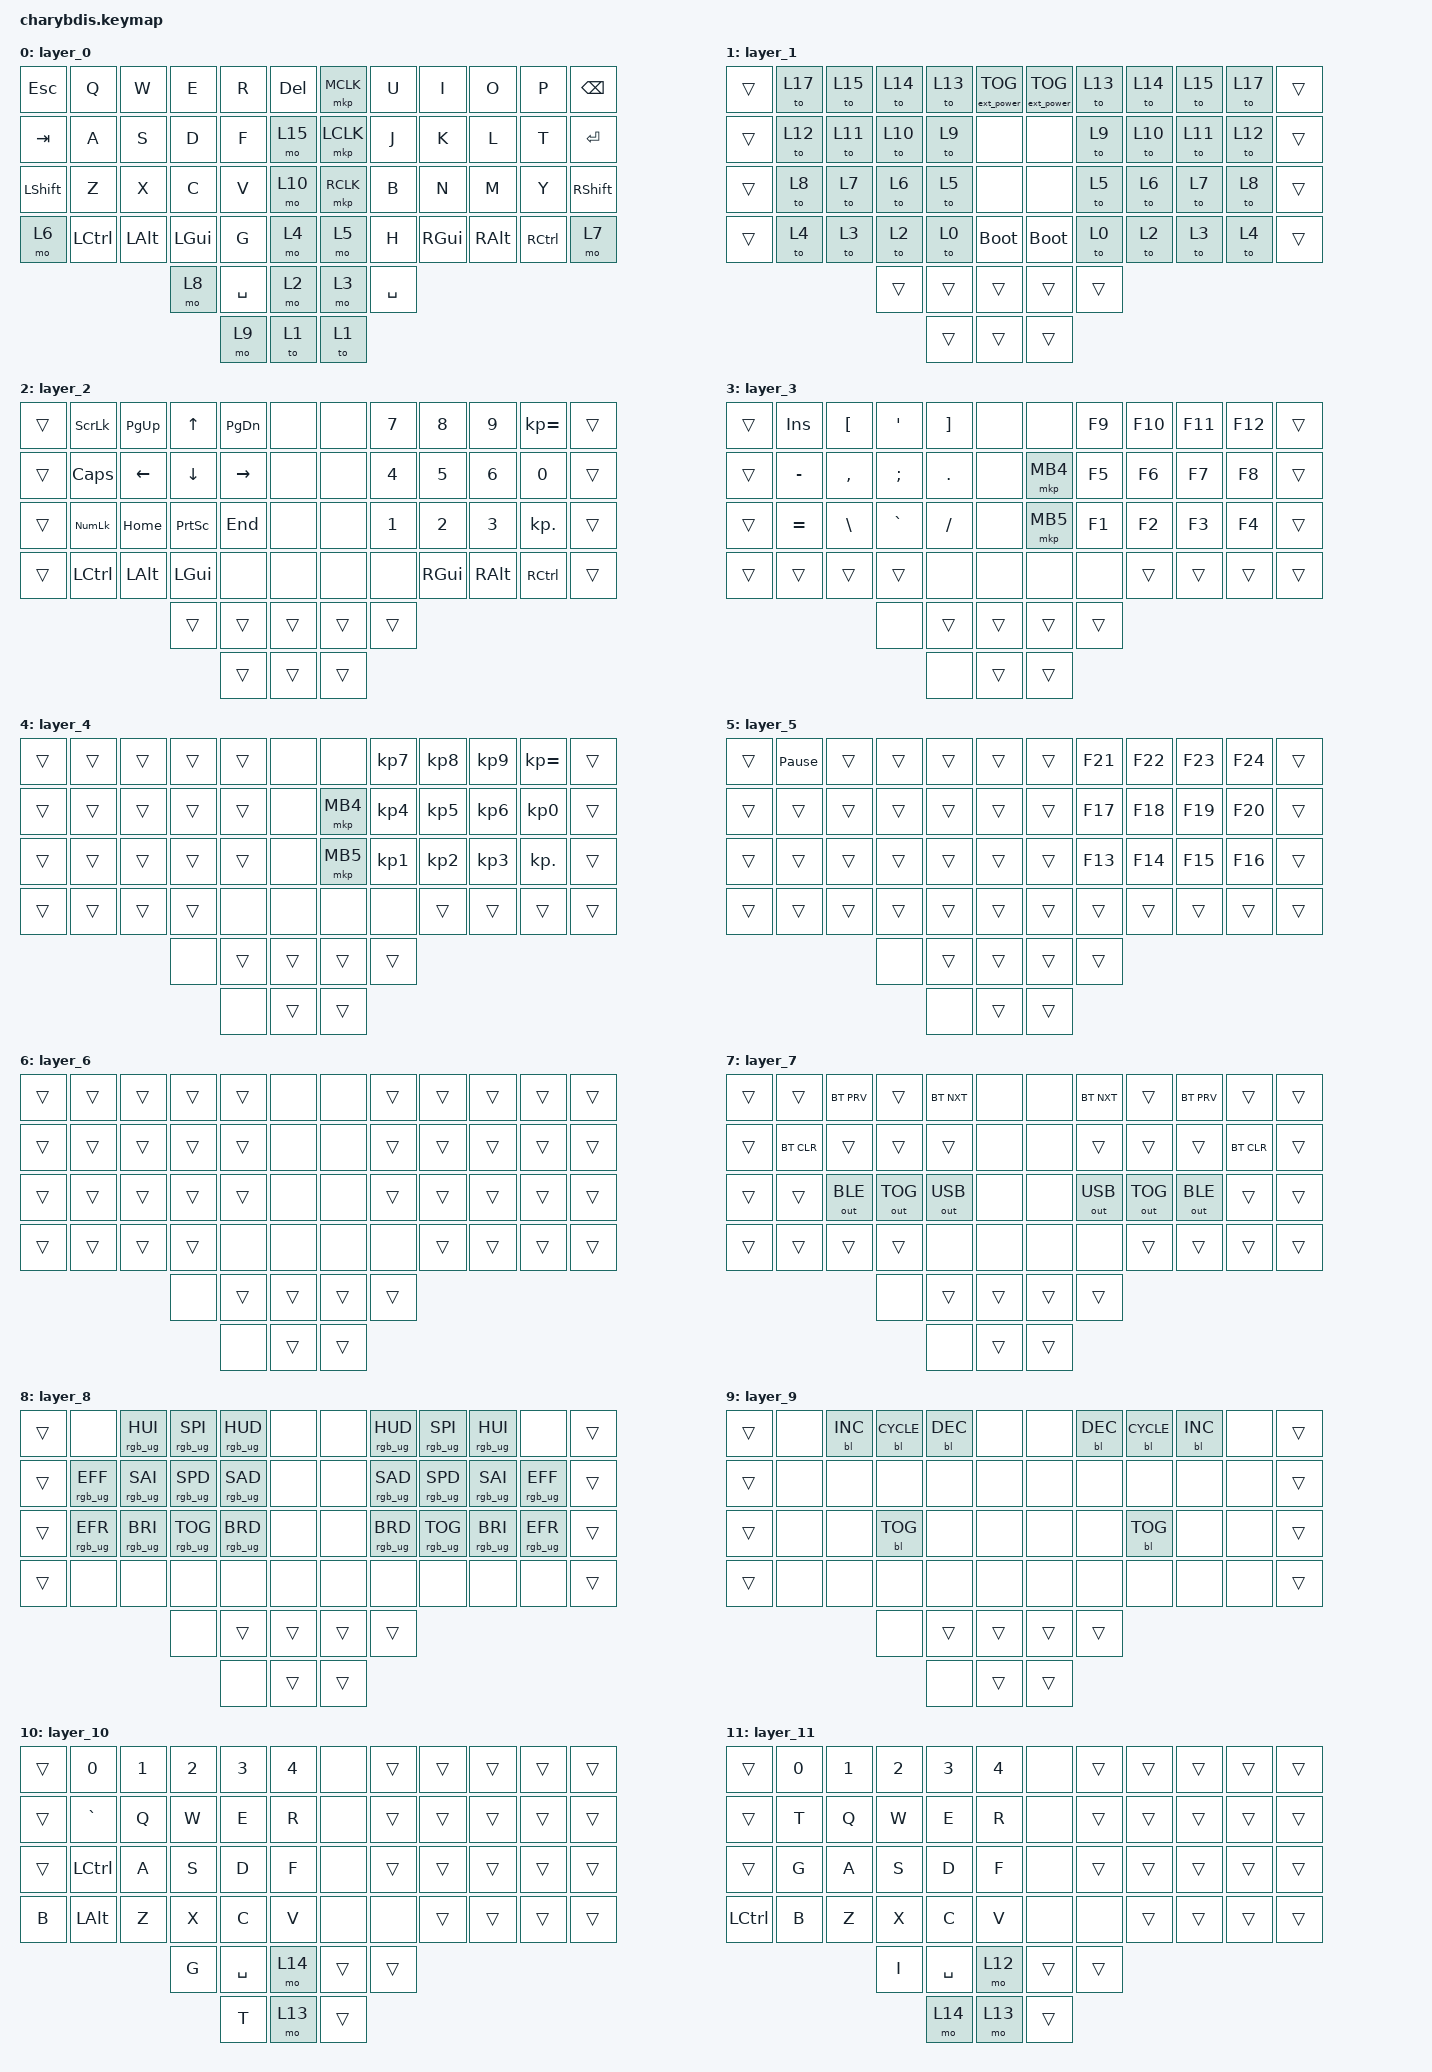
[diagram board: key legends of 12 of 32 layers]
#include <dt-bindings/zmk/keys.h>
#include <dt-bindings/zmk/ext_power.h>
#include <dt-bindings/zmk/bt.h>
#include <dt-bindings/zmk/mouse.h>
#include <dt-bindings/zmk/outputs.h>
#include <behaviors.dtsi>
#include <dt-bindings/zmk/rgb.h>
#include <dt-bindings/zmk/backlight.h>
//#include <dt-bindings/zmk/pointing.h>

&lt {
    tapping-term-ms = <200>;
    flavor = "balanced";
    quick-tap-ms = <150>;
};

/ {
    keymap {
        compatible = "zmk,keymap";

        layer_0 {
            bindings = <
&kp ESC    &kp Q      &kp W     &kp E     &kp R      &kp DEL    &mkp MCLK  &kp U      &kp I     &kp O     &kp P      &kp BSPC
&kp TAB    &kp A      &kp S     &kp D     &kp F      &mo 15     &mkp LCLK  &kp J      &kp K     &kp L     &kp T      &kp ENTER
&kp LSHFT  &kp Z      &kp X     &kp C     &kp V      &mo 10     &mkp RCLK  &kp B      &kp N     &kp M     &kp Y      &kp RSHFT
&mo 6      &kp LCTRL  &kp LALT  &kp LGUI  &kp G      &mo 4      &mo 5      &kp H      &kp RGUI  &kp RALT  &kp RCTRL  &mo 7
                                &mo 8     &kp SPACE  &mo 2      &mo 3      &kp SPACE
                                          &mo 9      &to 1      &to 1
            >;
            trackball-bindings = <&tmv_coarse>;
        };

        layer_1 {
            bindings = <
&trans  &to 17  &to 15  &to 14  &to 13  &ext_power EP_TOG    &ext_power EP_TOG  &to 13  &to 14  &to 15  &to 17  &trans
&trans  &to 12  &to 11  &to 10  &to 9   &none                &none              &to 9   &to 10  &to 11  &to 12  &trans
&trans  &to 8   &to 7   &to 6   &to 5   &none                &none              &to 5   &to 6   &to 7   &to 8   &trans
&trans  &to 4   &to 3   &to 2   &to 0   &bootloader          &bootloader        &to 0   &to 2   &to 3   &to 4   &trans
                        &trans  &trans  &trans               &trans             &trans
                                &trans  &trans               &trans
            >;
        };

        layer_2 {
            bindings = <
&trans  &kp SCROLLLOCK  &kp PG_UP  &kp UP           &kp PG_DN  &none     &none   &kp N7  &kp N8    &kp N9    &kp KP_EQUAL  &trans
&trans  &kp CAPS        &kp LEFT   &kp DOWN         &kp RIGHT  &none     &none   &kp N4  &kp N5    &kp N6    &kp N0        &trans
&trans  &kp KP_NUMLOCK  &kp HOME   &kp PRINTSCREEN  &kp END    &none     &none   &kp N1  &kp N2    &kp N3    &kp KP_DOT    &trans
&trans  &kp LCTRL       &kp LALT   &kp LGUI         &none      &none     &none   &none   &kp RGUI  &kp RALT  &kp RCTRL     &trans
                                   &trans           &trans     &trans    &trans  &trans
                                                    &trans     &trans    &trans
            >;
        };

        layer_3 {
            bindings = <
&trans  &kp INSERT  &kp LBKT   &kp SQT    &kp RBKT    &none     &none     &kp F9  &kp F10  &kp F11  &kp F12  &trans
&trans  &kp MINUS   &kp COMMA  &kp SEMI   &kp PERIOD  &none     &mkp MB4  &kp F5  &kp F6   &kp F7   &kp F8   &trans
&trans  &kp EQUAL   &kp BSLH   &kp GRAVE  &kp FSLH    &none     &mkp MB5  &kp F1  &kp F2   &kp F3   &kp F4   &trans
&trans  &trans      &trans     &trans     &none       &none     &none     &none   &trans   &trans   &trans   &trans
                               &none      &trans      &trans    &trans    &trans
                                          &none       &trans    &trans
            >;
        };

        layer_4 {
            bindings = <
&trans  &trans  &trans  &trans  &trans  &none     &none     &kp KP_N7  &kp KP_N8  &kp KP_N9  &kp KP_EQUAL  &trans
&trans  &trans  &trans  &trans  &trans  &none     &mkp MB4  &kp KP_N4  &kp KP_N5  &kp KP_N6  &kp KP_N0     &trans
&trans  &trans  &trans  &trans  &trans  &none     &mkp MB5  &kp KP_N1  &kp KP_N2  &kp KP_N3  &kp KP_DOT    &trans
&trans  &trans  &trans  &trans  &none   &none     &none     &none      &trans     &trans     &trans        &trans
                        &none   &trans  &trans    &trans    &trans
                                &none   &trans    &trans
            >;
        };

        layer_5 {
            bindings = <
&trans  &kp PAUSE_BREAK  &trans  &trans  &trans  &trans    &trans  &kp F21  &kp F22  &kp F23  &kp F24  &trans
&trans  &trans           &trans  &trans  &trans  &trans    &trans  &kp F17  &kp F18  &kp F19  &kp F20  &trans
&trans  &trans           &trans  &trans  &trans  &trans    &trans  &kp F13  &kp F14  &kp F15  &kp F16  &trans
&trans  &trans           &trans  &trans  &trans  &trans    &trans  &trans   &trans   &trans   &trans   &trans
                                 &none   &trans  &trans    &trans  &trans
                                         &none   &trans    &trans
            >;
        };

        layer_6 {
            bindings = <
&trans  &trans  &trans  &trans  &trans  &none     &none   &trans  &trans  &trans  &trans  &trans
&trans  &trans  &trans  &trans  &trans  &none     &none   &trans  &trans  &trans  &trans  &trans
&trans  &trans  &trans  &trans  &trans  &none     &none   &trans  &trans  &trans  &trans  &trans
&trans  &trans  &trans  &trans  &none   &none     &none   &none   &trans  &trans  &trans  &trans
                        &none   &trans  &trans    &trans  &trans
                                &none   &trans    &trans
            >;
        };

        layer_7 {
            bindings = <
&trans  &trans      &bt BT_PRV    &trans        &bt BT_NXT    &none     &none   &bt BT_NXT    &trans        &bt BT_PRV    &trans      &trans
&trans  &bt BT_CLR  &trans        &trans        &trans        &none     &none   &trans        &trans        &trans        &bt BT_CLR  &trans
&trans  &trans      &out OUT_BLE  &out OUT_TOG  &out OUT_USB  &none     &none   &out OUT_USB  &out OUT_TOG  &out OUT_BLE  &trans      &trans
&trans  &trans      &trans        &trans        &none         &none     &none   &none         &trans        &trans        &trans      &trans
                                  &none         &trans        &trans    &trans  &trans
                                                &none         &trans    &trans
            >;
        };

        layer_8 {
            bindings = <
&trans  &none            &rgb_ug RGB_HUI  &rgb_ug RGB_SPI  &rgb_ug RGB_HUD  &none     &none   &rgb_ug RGB_HUD  &rgb_ug RGB_SPI  &rgb_ug RGB_HUI  &none            &trans
&trans  &rgb_ug RGB_EFF  &rgb_ug RGB_SAI  &rgb_ug RGB_SPD  &rgb_ug RGB_SAD  &none     &none   &rgb_ug RGB_SAD  &rgb_ug RGB_SPD  &rgb_ug RGB_SAI  &rgb_ug RGB_EFF  &trans
&trans  &rgb_ug RGB_EFR  &rgb_ug RGB_BRI  &rgb_ug RGB_TOG  &rgb_ug RGB_BRD  &none     &none   &rgb_ug RGB_BRD  &rgb_ug RGB_TOG  &rgb_ug RGB_BRI  &rgb_ug RGB_EFR  &trans
&trans  &none            &none            &none            &none            &none     &none   &none            &none            &none            &none            &trans
                                          &none            &trans           &trans    &trans  &trans
                                                           &none            &trans    &trans
            >;
        };

        layer_9 {
            bindings = <
&trans  &none       &bl BL_INC  &bl BL_CYCLE  &bl BL_DEC  &none     &none   &bl BL_DEC  &bl BL_CYCLE  &bl BL_INC  &none  &trans
&trans  &none       &none       &none         &none       &none     &none   &none       &none         &none       &none  &trans
&trans  &none       &none       &bl BL_TOG    &none       &none     &none   &none       &bl BL_TOG    &none       &none  &trans
&trans  &none       &none       &none         &none       &none     &none   &none       &none         &none       &none  &trans
                                &none         &trans      &trans    &trans  &trans
                                              &none       &trans    &trans
            >;
        };

        layer_10 {
            bindings = <
&trans  &kp N0     &kp N1  &kp N2  &kp N3     &kp N4    &none   &trans  &trans  &trans  &trans  &trans
&trans  &kp GRAVE  &kp Q   &kp W   &kp E      &kp R     &none   &trans  &trans  &trans  &trans  &trans
&trans  &kp LCTRL  &kp A   &kp S   &kp D      &kp F     &none   &trans  &trans  &trans  &trans  &trans
&kp B   &kp LALT   &kp Z   &kp X   &kp C      &kp V     &none   &none   &trans  &trans  &trans  &trans
                           &kp G   &kp SPACE  &mo 14    &trans  &trans
                                   &kp T      &mo 13    &trans
            >;
        };

        layer_11 {
            bindings = <
&trans     &kp N0  &kp N1  &kp N2  &kp N3     &kp N4    &none   &trans  &trans  &trans  &trans  &trans
&trans     &kp T   &kp Q   &kp W   &kp E      &kp R     &none   &trans  &trans  &trans  &trans  &trans
&trans     &kp G   &kp A   &kp S   &kp D      &kp F     &none   &trans  &trans  &trans  &trans  &trans
&kp LCTRL  &kp B   &kp Z   &kp X   &kp C      &kp V     &none   &none   &trans  &trans  &trans  &trans
                           &kp I   &kp SPACE  &mo 12    &trans  &trans
                                   &mo 14     &mo 13    &trans
            >;
        };

        layer_12 {
            bindings = <
&trans    &kp N5         &kp N6  &kp N7    &kp N8     &kp N9    &none   &trans  &trans  &trans  &trans  &trans
&kp CAPS  &kp Y          &kp U   &kp W     &kp O      &kp P     &none   &trans  &trans  &trans  &trans  &trans
&trans    &kp PAGE_UP    &kp A   &kp S     &kp D      &kp H     &none   &trans  &trans  &trans  &trans  &trans
&trans    &kp PAGE_DOWN  &kp J   &kp K     &kp L      &kp N     &none   &none   &trans  &trans  &trans  &trans
                                 &kp M     &kp SPACE  &none     &trans  &trans
                                           &none      &none     &trans
            >;
        };

        layer_13 {
            bindings = <
&trans  &none     &none      &none       &none      &none          &none   &trans  &trans  &trans  &trans  &trans
&trans  &kp DEL   &kp LBKT   &kp RBKT    &kp BSLH   &kp MINUS      &none   &trans  &trans  &trans  &trans  &trans
&trans  &kp HOME  &kp SEMI   &kp SQT     &kp GRAVE  &kp EQUAL      &none   &trans  &trans  &trans  &trans  &trans
&trans  &kp END   &kp COMMA  &kp PERIOD  &kp FSLH   &kp KP_NUMLOCK   &none   &none   &trans  &trans  &trans  &trans
                             &kp INSERT  &kp SPACE  &none          &trans  &trans
                                         &none      &none          &trans
            >;
        };

        layer_14 {
            bindings = <
&trans  &kp N5  &kp N6   &kp N7   &kp N8   &kp N9     &none   &trans  &trans  &trans  &trans  &trans
&trans  &kp F1  &kp F4   &kp F3   &kp F2   &kp P      &none   &trans  &trans  &trans  &trans  &trans
&trans  &kp F5  &kp F8   &kp F7   &kp F6   &kp L      &none   &trans  &trans  &trans  &trans  &trans
&trans  &kp F9  &kp F12  &kp F11  &kp F10  &kp M      &none   &none   &trans  &trans  &trans  &trans
                         &kp H    &trans   &none      &trans  &trans
                                  &none    &none      &trans
            >;
        };


        layer_15 {
            bindings = <
&trans  &none  &none  &none  &none  &none     &none   &none  &none  &none  &none  &trans
&trans  &none  &none  &none  &none  &none     &none   &none  &none  &none  &none  &trans
&trans  &none  &none  &none  &none  &none     &none   &none  &none  &none  &none  &trans
&trans  &none  &none  &none  &none  &none     &none   &none  &none  &none  &none  &trans
                      &none  &none  &none     &none   &none
                            &none  &none     &none
            >;
            trackball-bindings = <&tsl>;
        };

        layer_16 {
            bindings = <
&kp BSPC   &kp P      &kp O     &kp I     &kp U      &mkp MCLK    &kp DEL  &kp R      &kp E     &kp W     &kp Q      &kp ESC
&kp ENTER  &kp T      &kp L     &kp K     &kp J      &mkp LCLK    &mo 31   &kp F      &kp D     &kp S     &kp A      &kp TAB
&kp RSHFT  &kp Y      &kp M     &kp N     &kp B      &mkp RCLK    &mo 26   &kp V      &kp C     &kp X     &kp Z      &kp LSHFT
&mo 22     &kp RCTRL  &kp RALT  &kp RGUI  &kp H      &mo 20       &mo 21   &kp G      &kp LGUI  &kp LALT  &kp LCTRL  &mo 23
                                &mo 24    &kp SPACE  &mo 18       &mo 19   &kp SPACE
                                          &mo 25     &to 17       &to 17
            >;
            trackball-bindings = <&tmv_coarse>;
        };

        layer_17 {
            bindings = <
&trans  &to 1   &to 31  &to 30  &to 29  &none          &none        &to 29  &to 30  &to 31  &to 1   &trans
&trans  &to 28  &to 27  &to 26  &to 25  &none          &none        &to 25  &to 26  &to 27  &to 28  &trans
&trans  &to 24  &to 25  &to 24  &to 23  &none          &none        &to 23  &to 24  &to 25  &to 24  &trans
&trans  &to 20  &to 19  &to 18  &to 16  &bootloader    &bootloader  &to 16  &to 18  &to 19  &to 20  &trans
                        &trans  &trans  &trans         &trans       &trans
                                &trans  &trans         &trans
            >;
        };

        layer_18 {
            bindings = <
&trans  &kp KP_EQUAL  &kp N9    &kp N8    &kp N7  &none     &none   &kp PG_DN  &kp UP           &kp PG_UP  &kp SCROLLLOCK  &trans
&trans  &kp N0        &kp N6    &kp N5    &kp N4  &none     &none   &kp RIGHT  &kp DOWN         &kp LEFT   &kp CAPS        &trans
&trans  &kp KP_DOT    &kp N3    &kp N2    &kp N1  &none     &none   &kp END    &kp PRINTSCREEN  &kp HOME   &kp KP_NUMLOCK  &trans
&trans  &kp RCTRL     &kp RALT  &kp RGUI  &none   &none     &none   &none      &kp LGUI         &kp LALT   &kp LCTRL       &trans
                                &trans    &trans  &trans    &trans  &trans
                                          &trans  &trans    &trans
            >;
        };

        layer_19 {
            bindings = <
&trans  &kp F12  &kp F11  &kp F10  &kp F9  &none     &none   &kp RBKT    &kp SQT    &kp LBKT   &kp INSERT  &trans
&trans  &kp F8   &kp F7   &kp F6   &kp F5  &mkp MB4  &none   &kp PERIOD  &kp SEMI   &kp COMMA  &kp MINUS   &trans
&trans  &kp F4   &kp F3   &kp F2   &kp F1  &mkp MB5  &none   &kp FSLH    &kp GRAVE  &kp BSLH   &kp EQUAL   &trans
&trans  &trans   &trans   &trans   &none   &none     &none   &none       &trans     &trans     &trans      &trans
                          &none    &trans  &trans    &trans  &trans
                                   &none   &trans    &trans
            >;
        };

        layer_20 {
            bindings = <
&trans  &kp KP_EQUAL  &kp KP_N9  &kp KP_N8  &kp KP_N7  &none     &none   &trans  &trans  &trans  &trans  &trans
&trans  &kp KP_N0     &kp KP_N6  &kp KP_N5  &kp KP_N4  &mkp MB4  &none   &trans  &trans  &trans  &trans  &trans
&trans  &kp KP_DOT    &kp KP_N3  &kp KP_N2  &kp KP_N1  &mkp MB5  &none   &trans  &trans  &trans  &trans  &trans
&trans  &trans        &trans     &trans     &none      &none     &none   &none   &trans  &trans  &trans  &trans
                                 &none      &trans     &trans    &trans  &trans
                                            &none      &trans    &trans
            >;
        };

        layer_21 {
            bindings = <
&trans  &kp F24  &kp F23  &kp F22  &kp F21  &none     &none   &trans  &trans  &trans  &kp PAUSE_BREAK  &trans
&trans  &kp F20  &kp F19  &kp F18  &kp F17  &none     &none   &trans  &trans  &trans  &trans           &trans
&trans  &kp F16  &kp F15  &kp F14  &kp F13  &none     &none   &trans  &trans  &trans  &trans           &trans
&trans  &trans   &trans   &trans   &none    &none     &none   &none   &trans  &trans  &trans           &trans
                          &none    &trans   &trans    &trans  &trans
                                   &none    &trans    &trans
            >;
        };

        layer_22 {
            bindings = <
&trans  &trans  &trans  &trans  &trans  &none     &none   &trans  &trans  &trans  &trans  &trans
&trans  &trans  &trans  &trans  &trans  &none     &none   &trans  &trans  &trans  &trans  &trans
&trans  &trans  &trans  &trans  &trans  &none     &none   &trans  &trans  &trans  &trans  &trans
&trans  &trans  &trans  &trans  &none   &none     &none   &none   &trans  &trans  &trans  &trans
                        &none   &trans  &trans    &trans  &trans
                                &none   &trans    &trans
            >;
        };

        layer_23 {
            bindings = <
&trans  &trans      &bt BT_NXT    &trans        &bt BT_PRV    &none     &none   &bt BT_PRV    &trans        &bt BT_NXT    &trans      &trans
&trans  &bt BT_CLR  &trans        &trans        &trans        &none     &none   &trans        &trans        &trans        &bt BT_CLR  &trans
&trans  &trans      &out OUT_USB  &out OUT_TOG  &out OUT_BLE  &none     &none   &out OUT_BLE  &out OUT_TOG  &out OUT_USB  &trans      &trans
&trans  &trans      &trans        &trans        &none         &none     &none   &none         &trans        &trans        &trans      &trans
                                  &none         &trans        &trans    &trans  &trans
                                                &none         &trans    &trans
            >;
        };

        layer_24 {
            bindings = <
&trans  &none            &rgb_ug RGB_HUD  &rgb_ug RGB_SPI  &rgb_ug RGB_HUI  &none     &none   &rgb_ug RGB_HUI  &rgb_ug RGB_SPI  &rgb_ug RGB_HUD  &none            &trans
&trans  &rgb_ug RGB_EFF  &rgb_ug RGB_SAD  &rgb_ug RGB_SPD  &rgb_ug RGB_SAI  &none     &none   &rgb_ug RGB_SAI  &rgb_ug RGB_SPD  &rgb_ug RGB_SAD  &rgb_ug RGB_EFF  &trans
&trans  &rgb_ug RGB_EFR  &rgb_ug RGB_BRD  &rgb_ug RGB_TOG  &rgb_ug RGB_BRI  &none     &none   &rgb_ug RGB_BRI  &rgb_ug RGB_TOG  &rgb_ug RGB_BRD  &rgb_ug RGB_EFR  &trans
&trans  &none            &none            &none            &none            &none     &none   &none            &none            &none            &none            &trans
                                          &none            &trans           &trans    &trans  &trans
                                                           &none            &trans    &trans
            >;
        };

        layer_25 {
            bindings = <
&trans  &none       &bl BL_INC  &bl BL_CYCLE  &bl BL_DEC  &none     &none   &bl BL_DEC  &bl BL_CYCLE  &bl BL_INC  &none  &trans
&trans  &none       &none       &none         &none       &none     &none   &none       &none         &none       &none  &trans
&trans  &none       &none       &bl BL_TOG    &none       &none     &none   &none       &bl BL_TOG    &none       &none  &trans
&trans  &none       &none       &none         &none       &none     &none   &none       &none         &none       &none  &trans
                                &none         &trans      &trans    &trans  &trans
                                              &none       &trans    &trans
            >;
        };

        layer_26 {
            bindings = <
&trans  &none  &none  &none  &none  &none     &none   &none  &none  &none  &none  &trans
&trans  &none  &none  &none  &none  &none     &none   &none  &none  &none  &none  &trans
&trans  &none  &none  &none  &none  &none     &none   &none  &none  &none  &none  &trans
&trans  &none  &none  &none  &none  &none     &none   &none  &none  &none  &none  &trans
                      &none  &trans &trans    &trans  &trans
                             &none  &trans    &trans
            >;
        };

        layer_27 {
            bindings = <
&trans  &trans  &trans  &trans  &trans  &none     &none   &trans  &trans  &trans  &trans  &trans
&trans  &trans  &trans  &trans  &trans  &none     &none   &trans  &trans  &trans  &trans  &trans
&trans  &trans  &trans  &trans  &trans  &none     &none   &trans  &trans  &trans  &trans  &trans
&trans  &trans  &trans  &trans  &none   &none     &none   &none   &trans  &trans  &trans  &trans
                        &none   &trans  &trans    &trans  &trans
                                &none   &trans    &trans
            >;
        };

        layer_28 {
            bindings = <
&trans  &trans  &trans  &trans  &trans  &none     &none   &trans  &trans  &trans  &trans  &trans
&trans  &trans  &trans  &trans  &trans  &none     &none   &trans  &trans  &trans  &trans  &trans
&trans  &trans  &trans  &trans  &trans  &none     &none   &trans  &trans  &trans  &trans  &trans
&trans  &trans  &trans  &trans  &none   &none     &none   &none   &trans  &trans  &trans  &trans
                        &none   &trans  &trans    &trans  &trans
                                &none   &trans    &trans
            >;
        };

        layer_29 {
            bindings = <
&trans  &trans  &trans  &trans  &trans  &none     &none   &trans  &trans  &trans  &trans  &trans
&trans  &trans  &trans  &trans  &trans  &none     &none   &trans  &trans  &trans  &trans  &trans
&trans  &trans  &trans  &trans  &trans  &none     &none   &trans  &trans  &trans  &trans  &trans
&trans  &trans  &trans  &trans  &none   &none     &none   &none   &trans  &trans  &trans  &trans
                        &none   &trans  &trans    &trans  &trans
                                &none   &trans    &trans
            >;
        };

        layer_30 {
            bindings = <
&trans  &trans  &trans  &trans  &trans  &none     &none   &trans  &trans  &trans  &trans  &trans
&trans  &trans  &trans  &trans  &trans  &none     &none   &trans  &trans  &trans  &trans  &trans
&trans  &trans  &trans  &trans  &trans  &none     &none   &trans  &trans  &trans  &trans  &trans
&trans  &trans  &trans  &trans  &none   &none     &none   &none   &trans  &trans  &trans  &trans
                        &none   &trans  &trans    &trans  &trans
                                &none   &trans    &trans
            >;
        };

        layer_31 {
            bindings = <
&trans  &none  &none  &none  &none  &none     &none   &none  &none  &none  &none  &trans
&trans  &none  &none  &none  &none  &none     &none   &none  &none  &none  &none  &trans
&trans  &none  &none  &none  &none  &none     &none   &none  &none  &none  &none  &trans
&trans  &none  &none  &none  &none  &none     &none   &none  &none  &none  &none  &trans
                      &none  &none  &none     &none   &none
                             &none  &none     &none
            >;
            trackball-bindings = <&tsl>;
        };
    };
};
